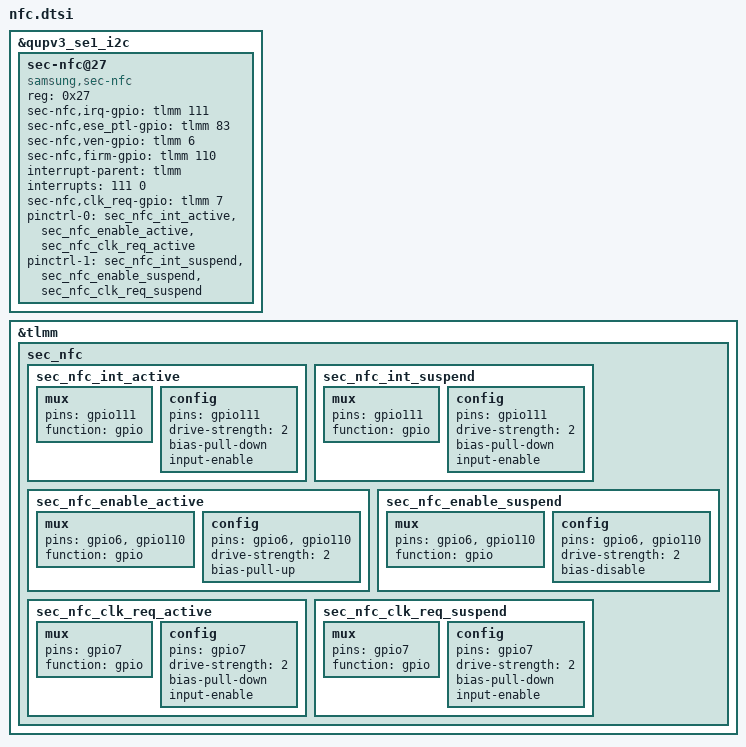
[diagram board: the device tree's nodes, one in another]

&qupv3_se1_i2c {
				sec-nfc@27{
					compatible = "samsung,sec-nfc";
					reg = <0x27>;
					sec-nfc,irq-gpio  = <&tlmm 111 0x00>;
					sec-nfc,ese_ptl-gpio = <&tlmm 83 0x00>;
					sec-nfc,ven-gpio = <&tlmm 6 0x00>;
					sec-nfc,firm-gpio = <&tlmm 110 0x00>;
					interrupt-parent = <&tlmm>;
					interrupts = <111 0>;
					


					
					sec-nfc,clk_req-gpio = <&tlmm 7  0x00>;
							pinctrl-names = "sec_nfc_active", "sec_nfc_suspend";
		pinctrl-0 = <&sec_nfc_int_active &sec_nfc_enable_active
				&sec_nfc_clk_req_active>;
		pinctrl-1 = <&sec_nfc_int_suspend &sec_nfc_enable_suspend
				&sec_nfc_clk_req_suspend>;
				
				};
};  



		
		
&tlmm {		
				sec_nfc {
			sec_nfc_int_active: sec_nfc_int_active {
				/* active state */
				mux {
					/* GPIO 111 NFC Read Interrupt */
					pins = "gpio111";
					function = "gpio";
				};

				config {
					pins = "gpio111";
					drive-strength = <2>; /* 2 MA */
					bias-pull-down;
                    input-enable;
				};
			};

			sec_nfc_int_suspend: sec_nfc_int_suspend {
				/* sleep state */
				mux {
					/* GPIO 111 NFC Read Interrupt */
					pins = "gpio111";
					function = "gpio";
				};

				config {
					pins = "gpio111";
					drive-strength = <2>; /* 2 MA */
					bias-pull-down;
                    input-enable;
				};
			};

			sec_nfc_enable_active: sec_nfc_enable_active {
				/* active state */
				mux {
					/* 6: Enable 110: Firmware */
					pins = "gpio6", "gpio110";
					function = "gpio";
				};

				config {
					pins = "gpio6", "gpio110";
					drive-strength = <2>; /* 2 MA */
					bias-pull-up;
				};
			};

			sec_nfc_enable_suspend: sec_nfc_enable_suspend {
				/* sleep state */
				mux {
					/* 6: Enable 110: Firmware */
					pins = "gpio6", "gpio110";
					function = "gpio";
				};

				config {
					pins = "gpio6", "gpio110";
					drive-strength = <2>; /* 2 MA */
					bias-disable;
				};
			};

			sec_nfc_clk_req_active: sec_nfc_clk_req_active {
				/* active state */
				mux {
					/* GPIO 7: NFC CLOCK REQUEST */
					pins = "gpio7";
					function = "gpio";
				};

				config {
					pins = "gpio7";
					drive-strength = <2>; /* 2 MA */
					bias-pull-down;
                    input-enable;
				};
			};

			sec_nfc_clk_req_suspend: sec_nfc_clk_req_suspend {
				/* sleep state */
				mux {
					/* GPIO 7: NFC CLOCK REQUEST */
					pins = "gpio7";
					function = "gpio";
				};

				config {
					pins = "gpio7";
					drive-strength = <2>; /* 2 MA */
					bias-pull-down;
                    input-enable;
				};
			};
		};
};
